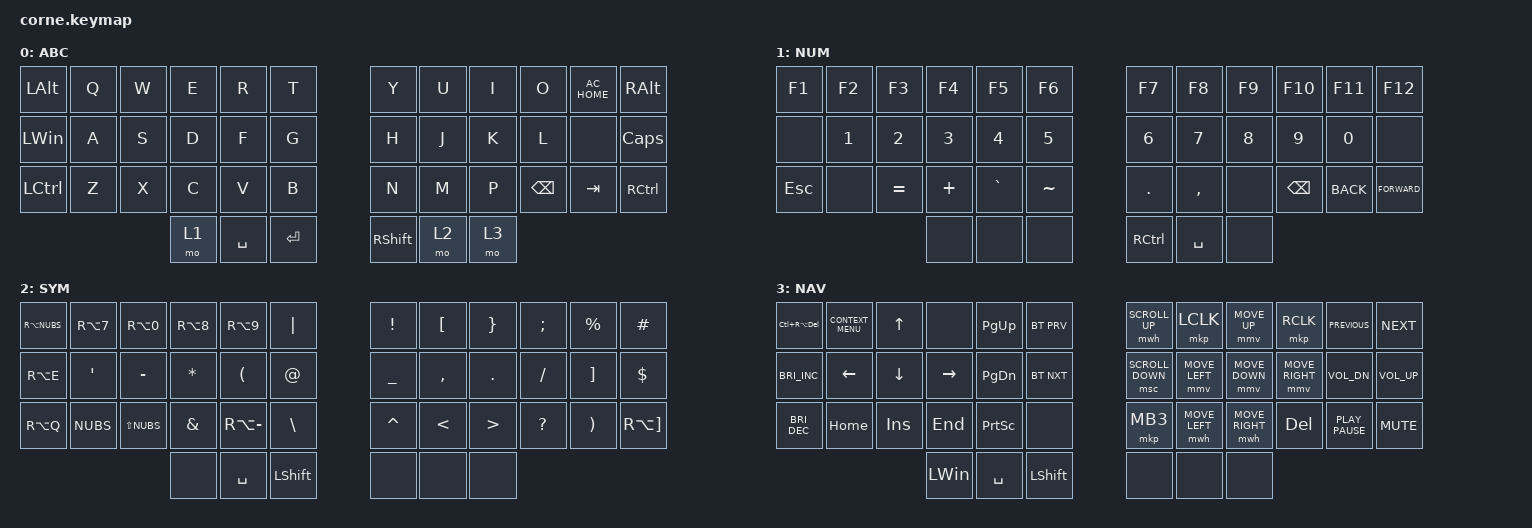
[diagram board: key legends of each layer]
/*
 * Copyright (c) 2020 The ZMK Contributors
 *
 * SPDX-License-Identifier: MIT
 */

#include <dt-bindings/zmk/mouse.h>
#include <behaviors.dtsi>
#include <dt-bindings/zmk/bt.h>
#include <dt-bindings/zmk/keys.h>

#define U_MOUSE_MOVE_MAX 3000                     /* <--- New max speed setting (default: 600, 1400) */

#undef MOVE_UP
#undef MOVE_DOWN
#undef MOVE_LEFT
#undef MOVE_RIGHT

#define MOVE_UP MOVE_VERT(-U_MOUSE_MOVE_MAX)
#define MOVE_DOWN MOVE_VERT(U_MOUSE_MOVE_MAX)
#define MOVE_LEFT MOVE_HOR(-U_MOUSE_MOVE_MAX)
#define MOVE_RIGHT MOVE_HOR(U_MOUSE_MOVE_MAX)
#define U_MOUSE_MOVE_TURBO_MAX 3000                     /* <--- New max speed setting (default: 600) */

#undef MOVE_UP_TURBO
#undef MOVE_DOWN_TURBO
#undef MOVE_LEFT_TURBO
#undef MOVE_RIGHT_TURBO

#define MOVE_UP_TURBO MOVE_VERT(-U_MOUSE_MOVE_TURBO_MAX)
#define MOVE_DOWN_TURBO MOVE_VERT(U_MOUSE_MOVE_TURBO_MAX)
#define MOVE_LEFT_TURBO MOVE_HOR(-U_MOUSE_MOVE_TURBO_MAX)
#define MOVE_RIGHT_TURBO MOVE_HOR(U_MOUSE_MOVE_TURBO_MAX)

&mmv {
    time-to-max-speed-ms = <1000>;             /* <--- How long time until max speed is reached (default: 500) */
};

/ {
    combos {
        compatible = "zmk,combos";

        blt_x {
            bindings = <&bt BT_CLR>;
            key-positions = <5 17>;
            layers = <3>;
            timeout-ms = <20>;
        };

        /*n1 {
            bindings = <&kp NUMBER_1>;
            key-positions = <6 7>;
            layers = <0>;
            timeout-ms = <20>;
        };

        n2 {
            bindings = <&kp NUMBER_2>;
            key-positions = <7 8>;
            layers = <0>;
            timeout-ms = <20>;
        };

        n3 {
            bindings = <&kp NUMBER_3>;
            key-positions = <8 9>;
            layers = <0>;
            timeout-ms = <20>;
        };

        n4 {
            bindings = <&kp NUMBER_4>;
            key-positions = <18 19>;
            layers = <0>;
            timeout-ms = <20>;
        };

        n5 {
            bindings = <&kp NUMBER_5>;
            key-positions = <19 20>;
            layers = <0>;
            timeout-ms = <20>;
        };

        n6 {
            bindings = <&kp NUMBER_6>;
            key-positions = <20 21>;
            layers = <0>;
            timeout-ms = <20>;
        };

        n7 {
            bindings = <&kp NUMBER_7>;
            key-positions = <30 31>;
            layers = <0>;
            timeout-ms = <20>;
        };

        n8 {
            bindings = <&kp NUMBER_8>;
            key-positions = <31 32>;
            layers = <0>;
            timeout-ms = <20>;
        };

        n9 {
            bindings = <&kp NUMBER_9>;
            key-positions = <32 33>;
            layers = <0>;
            timeout-ms = <20>;
        };
        
        n0 {
            bindings = <&kp N0>;
            key-positions = <33 34>;
            layers = <0>;
            timeout-ms = <20>;
        };*/
    };

    behaviors {
        HRM: HRM {
            compatible = "zmk,behavior-hold-tap";
            label = "HRM";
            bindings = <&kp>, <&kp>;

            #binding-cells = <2>;
            tapping-term-ms = <280>;
            quick-tap-ms = <175>;
            flavor = "balanced";
        };

        HRL: HRL {
            compatible = "zmk,behavior-hold-tap";
            label = "HRL";
            bindings = <&mo>, <&kp>;

            #binding-cells = <2>;
            tapping-term-ms = <280>;
            quick-tap-ms = <150>;
        };
    };

    keymap {
        compatible = "zmk,keymap";

        ABC {
            //       1        2     3      4        5         6
            //LINKS-----------------------------------------------------
            //L1/ |  ALT   |   Q   |   W   |   E    |   R   |     T     |
            //L2/ |  WIN   |   A   |   S   |   D    |   F   |     G     |
            //L3/ | STRG L |   Y   |   X   |   C    |   V   |     B     |
            //L4/ -------------------------| <NUM>  | Space |   Enter   |
            //RECHTS-----------------------------------------------------
            //R1/ |   Z    |   U   |   I   |  O     | Home  | ALT GR    |
            //R2/ |   H    |   J   |   K   |  L     |       | CAPS LOCK |
            //R3/ |   N    |   M   |   P   | Backsp |  Tab  | STRG R    |
            //R4/ | ShiftR | <SYM> | <NAV> |-----------------------------
            //    --------------------------

            bindings = <
&kp LEFT_ALT      &kp Q  &kp W  &kp E  &kp R      &kp T        &kp Y            &kp U  &kp I  &kp O          &kp C_AC_HOME  &kp RIGHT_ALT
&kp LEFT_WIN      &kp A  &kp S  &kp D  &kp F      &kp G        &kp H            &kp J  &kp K  &kp L          &none          &kp CLCK
&kp LEFT_CONTROL  &kp Z  &kp X  &kp C  &kp V      &kp B        &kp N            &kp M  &kp P  &kp BACKSPACE  &kp TAB        &kp RIGHT_CONTROL
                                &mo 1  &kp SPACE  &kp ENTER    &kp RIGHT_SHIFT  &mo 2  &mo 3
            >;
        };

        NUM {
            //      1         2       3         4        5       6
            //LINKS---------------------------------------------------
            //L1/ | F1     |  F2    | F3    |   F4   |   F5   |  F6  |
            //L2/ | TAB    |  1     | 2     |   3    |   4    |  5   |  
            //L3/ | ESC    |        | ´     |   `    |   ^    |  °   |
            //L4/  -------------------------|  XXX   |        |      |
            //RECHTS--------------------------------------------------
            //R1/ | F7     | F8     | F9    | F10    | F11    | F12  |
            //R2/ |  6     |  7     |  8    |  9     |  0     |      |
            //R3/ |  .     |  ,     |       | Backsp | Zurück |  Vor | <- Android
            //R4/ | ShiftR | Space  |       |-------------------------
            //    --------------------------

            bindings = <
&kp F1      &kp F2        &kp F3        &kp F4        &kp F5        &kp F6       &kp F7        &kp F8        &kp F9        &kp F10        &kp F11       &kp F12
&none       &kp NUMBER_1  &kp NUMBER_2  &kp NUMBER_3  &kp NUMBER_4  &kp N5       &kp NUMBER_6  &kp NUMBER_7  &kp NUMBER_8  &kp NUMBER_9   &kp NUMBER_0  &none
&kp ESCAPE  &none         &kp EQUAL     &kp PLUS      &kp GRAVE     &kp TILDE    &kp DOT       &kp COMMA     &none         &kp BACKSPACE  &kp K_BACK    &kp K_FORWARD
                                        &none         &none         &none        &kp RCTRL     &kp SPACE     &none
            >;
        };

        SYM {
            //       1     2     3      4       5        6
            //LINKS--------------------------------------------
            //L1/ |  |  |  {  |  }  |  [    |  ]     |   '    |
            //L2/ |  €  |  ä  |  ß  |  (    |  )     |   "    |
            //L3/ |  @  |  <  |  >  |  /    |  \     |   #    |
            //L4/ ------------------|       | Space  | ShiftL |
            //RECHTS-------------------------------------------
            //R1/ |  !  |  ü  |  *  |  ö    |  %     |   §    |
            //R2/ |  ?  |  ,  |  .  |  -    |  +     |   $    |
            //R3/ |  &  |  ;  |  :  |  _    |  =     |   ~    |
            //R4/ |     | XXX |     |--------------------------
            //    -------------------

            bindings = <
&kp RA(NUBS)  &kp RA(N7)  &kp RA(N0)    &kp RA(N8)  &kp RA(N9)            &kp PIPE          &kp EXCL   &kp LEFT_BRACKET  &kp RIGHT_BRACE   &kp SEMI      &kp PERCENT            &kp HASH
&kp RA(E)     &kp SQT     &kp MINUS     &kp STAR    &kp LEFT_PARENTHESIS  &kp AT            &kp UNDER  &kp COMMA         &kp DOT           &kp SLASH     &kp RIGHT_BRACKET      &kp DOLLAR
&kp RA(Q)     &kp NUBS    &kp LS(NUBS)  &kp AMPS    &kp RA(MINUS)         &kp BACKSLASH     &kp CARET  &kp LESS_THAN     &kp GREATER_THAN  &kp QUESTION  &kp RIGHT_PARENTHESIS  &kp RA(RIGHT_BRACKET)
                                        &none       &kp SPACE             &kp LEFT_SHIFT    &none      &none             &none
            >;
        };

        NAV {
            //      1              2              3               4              5             6
            //LINKS -------------------------------------------------------------------------------------------
            //L1/ | Strg+Alt+Ent | Menü         | Pfeil hoch    |              | Bild hoch   | Bluetooth prev |
            //L2/ | Helligk. +   | Pfeil links  | Pfeil runter  | Pfeil rechts | Bild runter | Bluetooth next |
            //L3/ | Helligk. -   | Pos1         | Einf          | Ende         | Druck       |                |
            //L4/  ---------------------------------------------|              | Space       | ShiftL         |
            //RECHTS ------------------------------------------------------------------------------------------
            //R1/ | Scroll up    | Linksklick   | Maus hoch     | Rechtsklick  | Prev        | Next           | <- Musik
            //R2/ | Scroll down  | Maus links   | Maus runter   | Maus rechts  | Volume -    | Volume +       |
            //R3/ | Mittelklick  | Scroll links | Scroll rechts | Enft         | Play/Pause  | Mute           |
            //R4/ |              | XXX         |                |----------------------------------------------
            //    -----------------------------------------------

            bindings = <
&kp LC(RA(DEL))       &kp K_CONTEXT_MENU  &kp UP_ARROW  &none         &kp PAGE_UP      &bt BT_PRV        &mwh SCROLL_UP    &mkp LCLK       &mmv MOVE_UP     &mkp RCLK        &kp K_PREVIOUS    &kp K_NEXT
&kp C_BRIGHTNESS_INC  &kp LEFT_ARROW      &kp DOWN      &kp RIGHT     &kp PAGE_DOWN    &bt BT_NXT        &msc SCROLL_DOWN  &mmv MOVE_LEFT  &mmv MOVE_DOWN   &mmv MOVE_RIGHT  &kp K_VOL_DN      &kp K_VOL_UP
&kp C_BRIGHTNESS_DEC  &kp HOME            &kp INSERT    &kp END       &kp PRINTSCREEN  &none             &mkp MB3          &mwh MOVE_LEFT  &mwh MOVE_RIGHT  &kp DEL          &kp K_PLAY_PAUSE  &kp K_MUTE
                                                        &kp LEFT_WIN  &kp SPACE        &kp LEFT_SHIFT    &none             &none           &none
            >;
        };
    };
};
